# onewire register map
Vendor: Texas Instruments
Peripheral module from a debugger description file (folder sc4e129bnczad).
Registers are 32-bit, read-write, no defined reset value unless marked. A register's access mark holds for its fields unless they carry their own. Offsets are as the file gives them; lines under a group give offsets from that group; [hi:lo] are bit positions; {n}, {i} and the like mark numbered series; 'fields as' and 'values as' point back to an identical list; <NAME> marks a mode.

## ONEWIRE0 — One wire register offsets
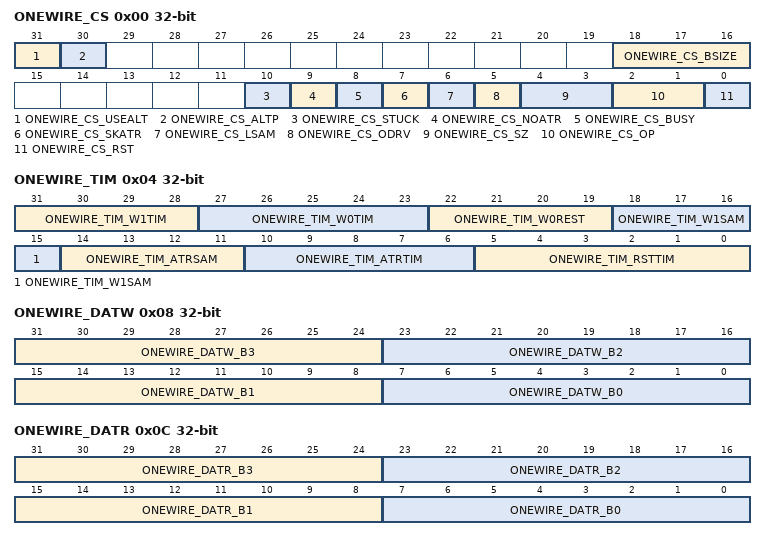
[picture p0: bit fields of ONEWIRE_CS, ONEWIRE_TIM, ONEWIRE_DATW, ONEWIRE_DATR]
0x00 ONEWIRE_CS — 1-Wire Control and Status
  [31] ONEWIRE_CS_USEALT — Two Wire Enable
  [30] ONEWIRE_CS_ALTP — Alternate Polarity Enable
  [18:16] ONEWIRE_CS_BSIZE — Last Byte Size
    0=8 bits (1 byte); 1=1 bit; {v}={v} bits (v=2..7)
  [10] ONEWIRE_CS_STUCK — STUCK Status
  [9] ONEWIRE_CS_NOATR — Answer-to-Reset Status
  [8] ONEWIRE_CS_BUSY — Busy Status
  [7] ONEWIRE_CS_SKATR — Skip Answer-to-Reset Enable
  [6] ONEWIRE_CS_LSAM — Late Sample Enable
  [5] ONEWIRE_CS_ODRV — Overdrive Enable
  [4:3] ONEWIRE_CS_SZ — Data Operation Size
  [2:1] ONEWIRE_CS_OP — Operation Request
    0=ONEWIRE_CS_OP_NONE (No operation); 1=ONEWIRE_CS_OP_RD (Read); 2=ONEWIRE_CS_OP_WR (Write); 3=ONEWIRE_CS_OP_WRRD (Write/Read)
  [0] ONEWIRE_CS_RST — Reset Request
0x04 ONEWIRE_TIM — 1-Wire Timing Override
  [31:28] ONEWIRE_TIM_W1TIM — Value '1' Timing
  [27:23] ONEWIRE_TIM_W0TIM — Value '0' Timing
  [22:19] ONEWIRE_TIM_W0REST — Rest Time
  [18:15] ONEWIRE_TIM_W1SAM — Sample Time
  [14:11] ONEWIRE_TIM_ATRSAM — Answer-to-Reset Sample
  [10:6] ONEWIRE_TIM_ATRTIM — Answer-to-Reset/Rest Period
  [5:0] ONEWIRE_TIM_RSTTIM — Reset Low Time
0x08 ONEWIRE_DATW — 1-Wire Data Write
  [31:24] ONEWIRE_DATW_B3 — Upper Data Byte
  [23:16] ONEWIRE_DATW_B2 — Upper Middle Data Byte
  [15:8] ONEWIRE_DATW_B1 — Lower Middle Data Byte
  [7:0] ONEWIRE_DATW_B0 — Lowest Data Byte
0x0C ONEWIRE_DATR — 1-Wire Data Read
  [31:24] ONEWIRE_DATR_B3 — Upper Data Byte
  [23:16] ONEWIRE_DATR_B2 — Upper Middle Data Byte
  [15:8] ONEWIRE_DATR_B1 — Lower Middle Data Byte
  [7:0] ONEWIRE_DATR_B0 — Lowest Data Byte
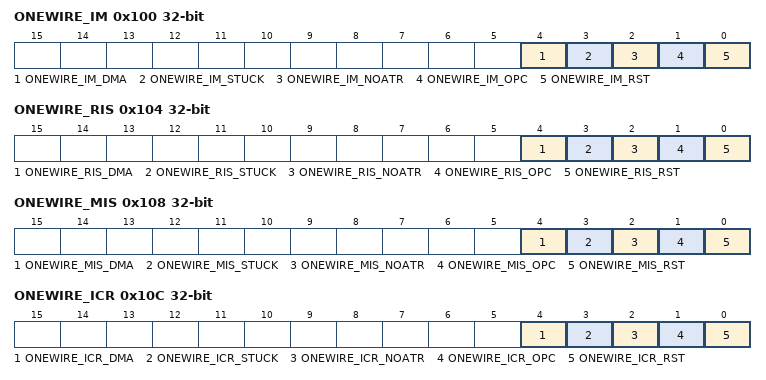
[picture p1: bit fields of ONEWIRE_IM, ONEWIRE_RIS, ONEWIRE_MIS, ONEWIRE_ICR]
0x100 ONEWIRE_IM — 1-Wire Interrupt Mask
  [4] ONEWIRE_IM_DMA — DMA Done Interrupt Mask
  [3] ONEWIRE_IM_STUCK — Stuck Status Interrupt Mask
  [2] ONEWIRE_IM_NOATR — No Answer-to-Reset Interrupt Mask
  [1] ONEWIRE_IM_OPC — Operation Complete Interrupt Mask
  [0] ONEWIRE_IM_RST — Reset Interrupt Mask
0x104 ONEWIRE_RIS ro — 1-Wire Raw Interrupt Status
  [4] ONEWIRE_RIS_DMA — DMA Done Raw Interrupt Status
  [3] ONEWIRE_RIS_STUCK — Stuck Status Raw Interrupt Status
  [2] ONEWIRE_RIS_NOATR — No Answer-to-Reset Raw Interrupt Status
  [1] ONEWIRE_RIS_OPC — Operation Complete Raw Interrupt Status
  [0] ONEWIRE_RIS_RST — Reset Raw Interrupt Status
0x108 ONEWIRE_MIS ro — 1-Wire Masked Interrupt Status
  [4] ONEWIRE_MIS_DMA — DMA Done Masked Interrupt Status
  [3] ONEWIRE_MIS_STUCK — Stuck Status Masked Interrupt Status
  [2] ONEWIRE_MIS_NOATR — No Answer-to-Reset Masked Interrupt Status
  [1] ONEWIRE_MIS_OPC — Operation Complete Masked Interrupt Status
  [0] ONEWIRE_MIS_RST — Reset Interrupt Mask
0x10C ONEWIRE_ICR — 1-Wire Interrupt Clear
  [4] ONEWIRE_ICR_DMA — DMA Done Interrupt Clear
  [3] ONEWIRE_ICR_STUCK — Stuck Status Interrupt Clear
  [2] ONEWIRE_ICR_NOATR — No Answer-to-Reset Interrupt Clear
  [1] ONEWIRE_ICR_OPC — Operation Complete Interrupt Clear
  [0] ONEWIRE_ICR_RST — Reset Interrupt Clear
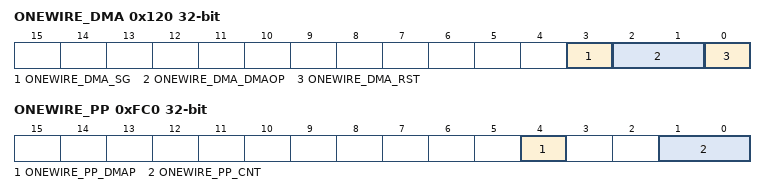
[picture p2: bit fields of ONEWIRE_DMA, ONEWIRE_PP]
0x120 ONEWIRE_DMA — 1-Wire uDMA Control
  [3] ONEWIRE_DMA_SG — Scatter-Gather Enable
  [2:1] ONEWIRE_DMA_DMAOP — uDMA Operation
    0=ONEWIRE_DMA_DMAOP_DIS (uDMA disabled); 1=ONEWIRE_DMA_DMAOP_RDSNG (uDMA single read: 1-Wire requests uDMA to read ONEWIREDATR register after each read transaction); 2=ONEWIRE_DMA_DMAOP_WRMUL (uDMA multiple write: 1-Wire requests uDMA to load whenever the ONEWIREDATW register is empty); 3=ONEWIRE_DMA_DMAOP_RDMUL (uDMA multiple read: An initial read occurs and subsequent reads start after uDMA has read the ONEWIREDATR register)
  [0] ONEWIRE_DMA_RST — uDMA Reset
0xFC0 ONEWIRE_PP ro — 1-Wire Peripheral Properties
  [4] ONEWIRE_PP_DMAP — uDMA Present
  [1:0] ONEWIRE_PP_CNT — 1-Wire Bus Count
